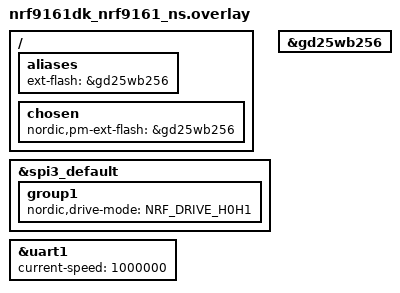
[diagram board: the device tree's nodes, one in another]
/*
 * Copyright (c) 2022 Nordic Semiconductor ASA
 *
 * SPDX-License-Identifier: LicenseRef-Nordic-5-Clause
 */


/* Enable high drive mode for the SPI3 pins to get a square signal at 8 MHz */
&spi3_default {
	group1 {
		nordic,drive-mode = <NRF_DRIVE_H0H1>;
	};
};

/* Enable UART1 at 1 megabaud for printing modem traces  */
&uart1 {
	status = "okay";
	current-speed = <1000000>;
};

/ {
	aliases {
		ext-flash = &gd25wb256;
	};

	/* Configure partition manager to use gd25wb256 as the external flash */
	chosen {
		nordic,pm-ext-flash = &gd25wb256;
	};
};

&gd25wb256 {
	status = "okay";
};
